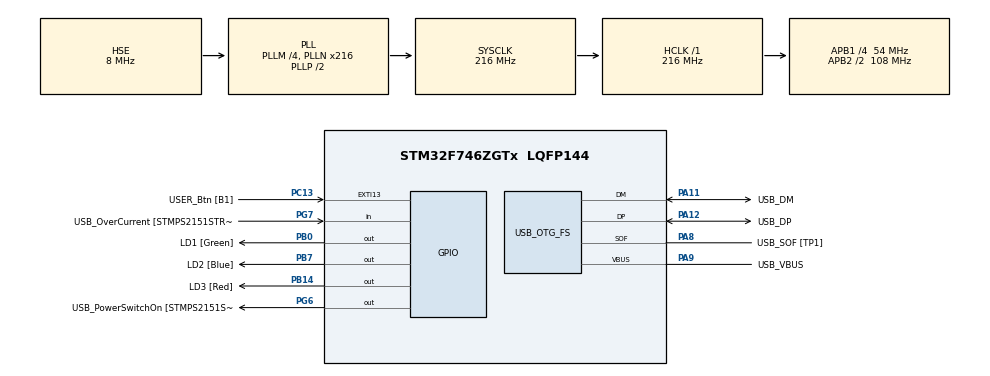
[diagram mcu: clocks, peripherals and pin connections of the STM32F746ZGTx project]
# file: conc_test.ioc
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CRC.CRCLength=CRC_POLYLENGTH_16B
CRC.DefaultInitValueUse=DEFAULT_INIT_VALUE_DISABLE
CRC.DefaultPolynomialUse=DEFAULT_POLYNOMIAL_DISABLE
CRC.InputDataInversionMode=CRC_INPUTDATA_INVERSION_BYTE
CRC.OutputDataInversionMode=CRC_OUTPUTDATA_INVERSION_ENABLE
Mcu.Family=STM32F7
Mcu.Name=STM32F746ZGTx
Mcu.Package=LQFP144
NVIC.OTG_FS_IRQn=true\:0\:0\:false\:false\:true\:false\:true\:true
NVIC.PriorityGroup=NVIC_PRIORITYGROUP_4
NVIC.TIM1_UP_TIM10_IRQn=true\:15\:0\:false\:false\:true\:false\:true\:true
NVIC.TimeBase=TIM1_UP_TIM10_IRQn
NVIC.TimeBaseIP=TIM1
PA10.GPIO_Label=USB_ID
PA10.Signal=USB_OTG_FS_ID
PA11.GPIO_Label=USB_DM
PA11.Mode=Device_Only
PA11.Signal=USB_OTG_FS_DM
PA12.GPIO_Label=USB_DP
PA12.Mode=Device_Only
PA12.Signal=USB_OTG_FS_DP
PA13.GPIO_Label=TMS
PA13.Mode=Serial_Wire
PA13.Signal=SYS_JTMS-SWDIO
PA14.GPIO_Label=TCK
PA14.Mode=Serial_Wire
PA14.Signal=SYS_JTCK-SWCLK
PA8.GPIO_Label=USB_SOF [TP1]
PA8.Mode=Activate_SOF_FS
PA8.Signal=USB_OTG_FS_SOF
PA9.GPIO_Label=USB_VBUS
PA9.Mode=Activate_VBUS
PA9.Signal=USB_OTG_FS_VBUS
PB0.GPIO_Label=LD1 [Green]
PB0.Signal=GPIO_Output
PB14.GPIO_Label=LD3 [Red]
PB14.Signal=GPIO_Output
PB7.GPIO_Label=LD2 [Blue]
PB7.Signal=GPIO_Output
PC13.GPIO_Label=USER_Btn [B1]
PC13.Signal=GPXTI13
PG6.GPIO_Label=USB_PowerSwitchOn [STMPS2151STR_EN]
PG6.Signal=GPIO_Output
PG7.GPIO_Label=USB_OverCurrent [STMPS2151STR_FAULT]
PG7.Signal=GPIO_Input
PH0/OSC_IN.GPIO_Label=MCO [STM32F103CBT6_PA8]
PH0/OSC_IN.Mode=HSE-External-Clock-Source
PH0/OSC_IN.Signal=RCC_OSC_IN
PH1/OSC_OUT.Mode=HSE-External-Clock-Source
PH1/OSC_OUT.Signal=RCC_OSC_OUT
ProjectManager.HeapSize=0x200
ProjectManager.StackSize=0x400
ProjectManager.TargetToolchain=STM32CubeIDE
RCC.48MHZClocksFreq_Value=24000000
RCC.AHBFreq_Value=216000000
RCC.APB1CLKDivider=RCC_HCLK_DIV4
RCC.APB1Freq_Value=54000000
RCC.APB1TimFreq_Value=108000000
RCC.APB2CLKDivider=RCC_HCLK_DIV2
RCC.APB2Freq_Value=108000000
RCC.APB2TimFreq_Value=216000000
RCC.CortexFreq_Value=216000000
RCC.HCLKFreq_Value=216000000
RCC.HSE_VALUE=8000000
RCC.HSI_VALUE=16000000
RCC.LSE_VALUE=32768
RCC.PLLM=4
RCC.PLLMUL=RCC_PLL_MUL9
RCC.PLLN=216
RCC.PLLQ=9
RCC.PRESCALERUSB=RCC_USBCLKSOURCE_PLL_DIV1_5
RCC.SYSCLKFreq_VALUE=216000000
RCC.SYSCLKSource=RCC_SYSCLKSOURCE_PLLCLK
RCC.SYSCLKSourceVirtual=RCC_SYSCLKSOURCE_PLLCLK
RCC.USBFreq_Value=48000000
RCC.VCOOutputFreq_Value=432000000
USB_DEVICE.CLASS_NAME_FS=CDC
USB_DEVICE.VirtualMode-CDC_FS=Cdc
USB_DEVICE.VirtualModeFS=Cdc_FS
USB_OTG_FS.VirtualMode=Device_Only
VP_CRC_VS_CRC.Mode=CRC_Activate
VP_SYS_VS_tim1.Mode=TIM1
VP_USB_DEVICE_VS_USB_DEVICE_CDC_FS.Mode=CDC_FS
board=NUCLEO-F746ZG

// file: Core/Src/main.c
/* USER CODE BEGIN Header */
/**
  ******************************************************************************
  * @file           : main.c
  * @brief          : Main program body
  ******************************************************************************
  * @attention
  *
  * Copyright (c) 2022 STMicroelectronics.
  * All rights reserved.
  *
  * This software is licensed under terms that can be found in the LICENSE file
  * in the root directory of this software component.
  * If no LICENSE file comes with this software, it is provided AS-IS.
  *
  ******************************************************************************
  */
/* USER CODE END Header */
#include "main.h"
#include "usb_device.h"

/* USER CODE BEGIN Includes */
#include "tasks_manager.h"
#include "usb_tasks.h"
/* USER CODE END Includes */

CRC_HandleTypeDef hcrc;

void SystemClock_Config(void);
static void MX_GPIO_Init(void);
static void MX_CRC_Init(void);

int main(void)
{

  /* MCU Configuration--------------------------------------------------------*/

  /* Reset of all peripherals, Initializes the Flash interface and the Systick. */
  HAL_Init();

  /* Configure the system clock */
  SystemClock_Config();

  /* Initialize all configured peripherals */
  MX_GPIO_Init();
  //MX_USB_DEVICE_Init();
  MX_CRC_Init();
  /* USER CODE BEGIN 2 */

  Start_USB_cmd_tasks();
  Start_UARTrx_tasks();

  vTaskStartScheduler();
  /* USER CODE END 2 */

  /* Infinite loop */
  while (1)
  {

  }
}

void SystemClock_Config(void)
{
  RCC_OscInitTypeDef RCC_OscInitStruct = {0};
  RCC_ClkInitTypeDef RCC_ClkInitStruct = {0};

  /** Configure the main internal regulator output voltage
  */
  __HAL_RCC_PWR_CLK_ENABLE();
  __HAL_PWR_VOLTAGESCALING_CONFIG(PWR_REGULATOR_VOLTAGE_SCALE1);

  /** Initializes the RCC Oscillators according to the specified parameters
  * in the RCC_OscInitTypeDef structure.
  */
  RCC_OscInitStruct.OscillatorType = RCC_OSCILLATORTYPE_HSE;
  RCC_OscInitStruct.HSEState = RCC_HSE_BYPASS;
  RCC_OscInitStruct.PLL.PLLState = RCC_PLL_ON;
  RCC_OscInitStruct.PLL.PLLSource = RCC_PLLSOURCE_HSE;
  RCC_OscInitStruct.PLL.PLLM = 4;
  RCC_OscInitStruct.PLL.PLLN = 216;
  RCC_OscInitStruct.PLL.PLLP = RCC_PLLP_DIV2;
  RCC_OscInitStruct.PLL.PLLQ = 9;
  if (HAL_RCC_OscConfig(&RCC_OscInitStruct) != HAL_OK)
  {
    Error_Handler();
  }

  /** Activate the Over-Drive mode
  */
  if (HAL_PWREx_EnableOverDrive() != HAL_OK)
  {
    Error_Handler();
  }

  /** Initializes the CPU, AHB and APB buses clocks
  */
  RCC_ClkInitStruct.ClockType = RCC_CLOCKTYPE_HCLK|RCC_CLOCKTYPE_SYSCLK
                              |RCC_CLOCKTYPE_PCLK1|RCC_CLOCKTYPE_PCLK2;
  RCC_ClkInitStruct.SYSCLKSource = RCC_SYSCLKSOURCE_PLLCLK;
  RCC_ClkInitStruct.AHBCLKDivider = RCC_SYSCLK_DIV1;
  RCC_ClkInitStruct.APB1CLKDivider = RCC_HCLK_DIV4;
  RCC_ClkInitStruct.APB2CLKDivider = RCC_HCLK_DIV2;

  if (HAL_RCC_ClockConfig(&RCC_ClkInitStruct, FLASH_LATENCY_7) != HAL_OK)
  {
    Error_Handler();
  }
}

static void MX_CRC_Init(void)
{

  hcrc.Instance = CRC;
  hcrc.Init.CRCLength = CRC_POLYLENGTH_16B;
  hcrc.Init.GeneratingPolynomial    = 0x8005;
  hcrc.Init.DefaultInitValueUse = 0;

  hcrc.Init.DefaultPolynomialUse = DEFAULT_POLYNOMIAL_DISABLE;
  hcrc.Init.DefaultInitValueUse = DEFAULT_INIT_VALUE_DISABLE;
  hcrc.Init.InputDataInversionMode = CRC_INPUTDATA_INVERSION_BYTE;
  hcrc.Init.OutputDataInversionMode = CRC_OUTPUTDATA_INVERSION_ENABLE;
  hcrc.InputDataFormat = CRC_INPUTDATA_FORMAT_BYTES;
  if (HAL_CRC_Init(&hcrc) != HAL_OK)
  {
    Error_Handler();
  }
  /* USER CODE BEGIN CRC_Init 2 */
 /* hcrc.Instance = CRC;

  hcrc.Init.CRCLength = CRC_POLYLENGTH_16B;
  hcrc.Init.GeneratingPolynomial    = 0x8005;
  hcrc.Init.DefaultInitValueUse = 0;

  hcrc.Init.DefaultPolynomialUse = DEFAULT_POLYNOMIAL_DISABLE;
  hcrc.Init.DefaultInitValueUse = DEFAULT_INIT_VALUE_DISABLE;
  hcrc.Init.InputDataInversionMode = CRC_INPUTDATA_INVERSION_BYTE;
  hcrc.Init.OutputDataInversionMode = CRC_OUTPUTDATA_INVERSION_ENABLE;
  hcrc.InputDataFormat = CRC_INPUTDATA_FORMAT_BYTES;*/
  /* USER CODE END CRC_Init 2 */

}

static void MX_GPIO_Init(void)
{
  GPIO_InitTypeDef GPIO_InitStruct = {0};

  /* GPIO Ports Clock Enable */
  __HAL_RCC_GPIOC_CLK_ENABLE();
  __HAL_RCC_GPIOH_CLK_ENABLE();
  __HAL_RCC_GPIOB_CLK_ENABLE();
  __HAL_RCC_GPIOG_CLK_ENABLE();
  __HAL_RCC_GPIOA_CLK_ENABLE();

  /*Configure GPIO pin Output Level */
  HAL_GPIO_WritePin(GPIOB, LD1_Pin|LD3_Pin|LD2_Pin, GPIO_PIN_RESET);

  /*Configure GPIO pin Output Level */
  HAL_GPIO_WritePin(USB_PowerSwitchOn_GPIO_Port, USB_PowerSwitchOn_Pin, GPIO_PIN_RESET);

  /*Configure GPIO pin : USER_Btn_Pin */
  GPIO_InitStruct.Pin = USER_Btn_Pin;
  GPIO_InitStruct.Mode = GPIO_MODE_IT_RISING;
  GPIO_InitStruct.Pull = GPIO_NOPULL;
  HAL_GPIO_Init(USER_Btn_GPIO_Port, &GPIO_InitStruct);

  /*Configure GPIO pins : LD1_Pin LD3_Pin LD2_Pin */
  GPIO_InitStruct.Pin = LD1_Pin|LD3_Pin|LD2_Pin;
  GPIO_InitStruct.Mode = GPIO_MODE_OUTPUT_PP;
  GPIO_InitStruct.Pull = GPIO_NOPULL;
  GPIO_InitStruct.Speed = GPIO_SPEED_FREQ_LOW;
  HAL_GPIO_Init(GPIOB, &GPIO_InitStruct);

  /*Configure GPIO pin : USB_PowerSwitchOn_Pin */
  GPIO_InitStruct.Pin = USB_PowerSwitchOn_Pin;
  GPIO_InitStruct.Mode = GPIO_MODE_OUTPUT_PP;
  GPIO_InitStruct.Pull = GPIO_NOPULL;
  GPIO_InitStruct.Speed = GPIO_SPEED_FREQ_LOW;
  HAL_GPIO_Init(USB_PowerSwitchOn_GPIO_Port, &GPIO_InitStruct);

  /*Configure GPIO pin : USB_OverCurrent_Pin */
  GPIO_InitStruct.Pin = USB_OverCurrent_Pin;
  GPIO_InitStruct.Mode = GPIO_MODE_INPUT;
  GPIO_InitStruct.Pull = GPIO_NOPULL;
  HAL_GPIO_Init(USB_OverCurrent_GPIO_Port, &GPIO_InitStruct);

}

void HAL_TIM_PeriodElapsedCallback(TIM_HandleTypeDef *htim)
{
  if (htim->Instance == TIM1) {
    HAL_IncTick();
  }
}

void Error_Handler(void)
{
  __disable_irq();
  while (1)
  {
  }
}
